# SIM3U164_B register map
File version: 1
CPU: 
Registers are 32-bit, read-write, reset 0x0 unless marked. A register's access mark holds for its fields unless they carry their own. Offsets are from the block's base; [hi:lo] are bit positions.

## PMU_0
Base 0x40048000
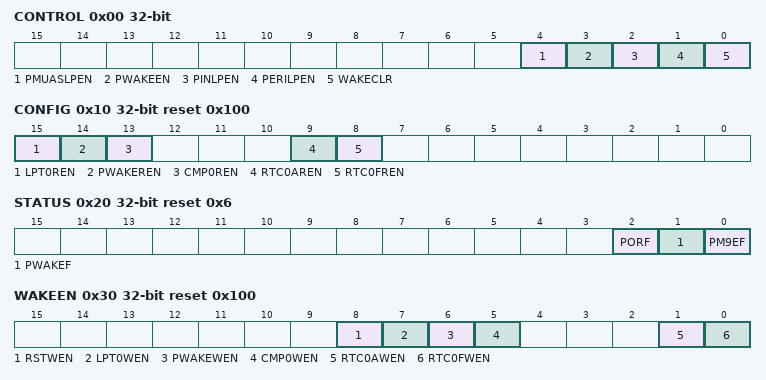
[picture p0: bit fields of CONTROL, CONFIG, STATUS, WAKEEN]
0x00 CONTROL — Module Control
  [4] PMUASLPEN — PMU Asleep Pin Enable.
    0=DISABLED (Disable the PMU Asleep pin.); 1=ENABLED (Enable the PMU Asleep pin.)
  [3] PWAKEEN — Pin Wake Match Enable.
    0=DISABLED (Disable Pin Wake.); 1=ENABLED (Enable Pin Wake.)
  [2] PINLPEN — Pin Low Power Enable.
    0=DISABLED (Disable the pin low power state.); 1=ENABLED (Enable the pin low power state. The pins will not be accessible in this state.)
  [1] PERILPEN — Peripheral Low Power Enable.
    0=DISABLED (Disable the peripheral low power state.); 1=ENABLED (Enable the peripheral low power state. The peripherals will not be accessible in this state.)
  [0] WAKECLR wo — Wakeup Source Clear.
    0=CLEAR (Clear all wakeup sources.)
0x10 CONFIG reset 0x100 — Module Configuration
  [15] LPT0REN — Low Power Timer RTC0/LPTIMER0 Reset Enable.
    0=DISABLED (An LPTIMER0 event does not cause the RTC0 and LPTIMER0 modules to reset.); 1=ENABLED (An LPTIMER0 event causes the RTC0 and LPTIMER0 modules to reset.)
  [14] PWAKEREN — Pin Wake RTC0/LPTIMER0 Reset Enable.
    0=DISABLED (A Pin Wake event does not cause the RTC0 and LPTIMER0 modules to reset.); 1=ENABLED (A Pin Wake event causes the RTC0 and LPTIMER0 modules to reset.)
  [13] CMP0REN — Comparator 0 RTC0/LPTIMER0 Reset Enable.
    0=DISABLED (A Comparator 0 event does not cause the RTC0 and LPTIMER0 modules to reset.); 1=ENABLED (A Comparator 0 event causes the RTC0 and LPTIMER0 modules to reset.)
  [9] RTC0AREN — RTC0 Alarm RTC0/LPTIMER0 Reset Enable.
    0=DISABLED (An RTC0 alarm event does not cause the RTC0 and LPTIMER0 modules to reset.); 1=ENABLED (An RTC0 alarm event causes the RTC0 and LPTIMER0 modules to reset.)
  [8] RTC0FREN — RTC0 Fail RTC0/LPTIMER0 Reset Enable.
    0=DISABLED (An RTC0 fail event does not cause the RTC0 and LPTIMER0 modules to reset.); 1=ENABLED (An RTC0 fail event causes the RTC0 and LPTIMER0 modules to reset.)
0x20 STATUS reset 0x6 — Module Status
  [2] PORF — Power-On Reset Flag.
    0=NOT_SET (A power-on reset did not occur since the last time PORF was cleared.); 1=SET (A power-on reset occurred.)
  [1] PWAKEF ro — Pin Wake Status Flag.
    0=SET (A Pin Wake event has occurred.); 1=NOT_SET (A Pin Wake event has not occurred.)
  [0] PM9EF — Power Mode 9 Exited Flag.
    0=NOT_SET (The device has not exited Power Mode 9.); 1=SET (The device has exited Power Mode 9. This bit must be cleared by firmware.)
0x30 WAKEEN reset 0x100 — Wake Source Enable
  [8] RSTWEN — Reset Pin Wake Enable.
    0=DISABLED (A /RESET Pin event does not wake the device.); 1=ENABLED (A /RESET Pin event awakens the device.)
  [7] LPT0WEN — Low Power Timer Wake Enable.
    0=DISABLED (An LPTIMER0 event does not wake the device.); 1=ENABLED (An LPTIMER0 event awakens the device.)
  [6] PWAKEWEN — Pin Wake Wake Enable.
    0=DISABLED (A Pin Wake event does not wake the device.); 1=ENABLED (A Pin Wake event awakens the device.)
  [5] CMP0WEN — Comparator 0 Wake Enable.
    0=DISABLED (A Comparator 0 event does not wake the device.); 1=ENABLED (A Comparator 0 event awakens the device.)
  [1] RTC0AWEN — RTC0 Alarm Wake Enable.
    0=DISABLED (An RTC0 alarm event does not wake the device.); 1=ENABLED (An RTC0 alarm event awakens the device.)
  [0] RTC0FWEN — RTC0 Fail Wake Enable.
    0=DISABLED (An RTC0 fail event does not wake the device.); 1=ENABLED (An RTC0 fail event awakens the device.)
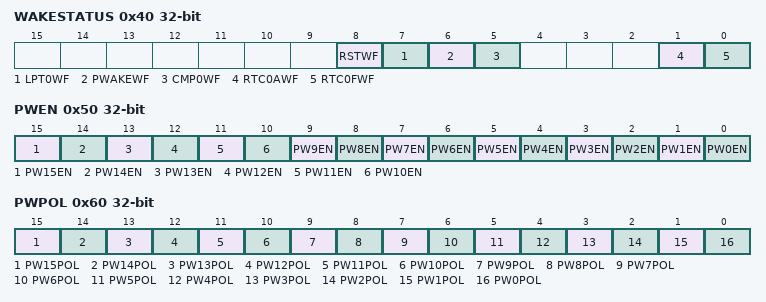
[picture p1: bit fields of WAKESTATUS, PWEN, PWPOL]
0x40 WAKESTATUS — Wake Source Status
  [8] RSTWF ro — Reset Pin Wake Flag.
    0=NOT_SET (A /RESET Pin event did not wake the device.); 1=SET (A /RESET Pin event woke the device.)
  [7] LPT0WF ro — Low Power Timer Wake Flag.
    0=NOT_SET (An LPTIMER0 event did not wake the device.); 1=SET (An LPTIMER0 event woke the device.)
  [6] PWAKEWF ro — Pin Wake Wake Flag.
    0=NOT_SET (A Pin Wake event did not wake the device.); 1=SET (A Pin Wake event woke the device.)
  [5] CMP0WF ro — Comparator 0 Wake Flag.
    0=NOT_SET (A Comparator 0 event did not wake the device.); 1=SET (A Comparator 0 event woke the device.)
  [1] RTC0AWF ro — RTC0 Alarm Wake Flag.
    0=NOT_SET (An RTC0 alarm event did not wake the device.); 1=SET (An RTC0 alarm event woke the device.)
  [0] RTC0FWF ro — RTC0 Fail Wake Flag.
    0=NOT_SET (An RTC0 fail event did not wake the device.); 1=SET (An RTC0 fail event woke the device.)
0x50 PWEN — Pin Wake Pin Enable
  [15] PW15EN — WAKE.15 Enable.
    0=DISABLED (WAKE.15 (PB3.3) is not used in the Pin Wake comparison.); 1=ENABLED (WAKE.15 (PB3.3) is used in the Pin Wake comparison.)
  [14] PW14EN — WAKE.14 Enable.
    0=DISABLED (WAKE.14 (PB3.2) is not used in the Pin Wake comparison.); 1=ENABLED (WAKE.14 (PB3.2) is used in the Pin Wake comparison.)
  [13] PW13EN — WAKE.13 Enable.
    0=DISABLED (WAKE.13 (PB3.1) is not used in the Pin Wake comparison.); 1=ENABLED (WAKE.13 (PB3.1) is used in the Pin Wake comparison.)
  [12] PW12EN — WAKE.12 Enable.
    0=DISABLED (WAKE.12 (PB3.0) is not used in the Pin Wake comparison.); 1=ENABLED (WAKE.12 (PB3.0) is used in the Pin Wake comparison.)
  [11] PW11EN — WAKE.11 Enable.
    0=DISABLED (WAKE.11 (RESERVED) is not used in the Pin Wake comparison.); 1=ENABLED (WAKE.11 (RESERVED) is used in the Pin Wake comparison.)
  [10] PW10EN — WAKE.10 Enable.
    0=DISABLED (WAKE.10 (RESERVED) is not used in the Pin Wake comparison.); 1=ENABLED (WAKE.10 (RESERVED) is used in the Pin Wake comparison.)
  [9] PW9EN — WAKE.9 Enable.
    0=DISABLED (WAKE.9 (RESERVED) is not used in the Pin Wake comparison.); 1=ENABLED (WAKE.9 (RESERVED) is used in the Pin Wake comparison.)
  [8] PW8EN — WAKE.8 Enable.
    0=DISABLED (WAKE.8 (RESERVED) is not used in the Pin Wake comparison.); 1=ENABLED (WAKE.8 (RESERVED) is used in the Pin Wake comparison.)
  [7] PW7EN — WAKE.7 Enable.
    0=DISABLED (WAKE.7 (RESERVED) is not used in the Pin Wake comparison.); 1=ENABLED (WAKE.7 (RESERVED) is used in the Pin Wake comparison.)
  [6] PW6EN — WAKE.6 Enable.
    0=DISABLED (WAKE.6 (RESERVED) is not used in the Pin Wake comparison.); 1=ENABLED (WAKE.6 (RESERVED) is used in the Pin Wake comparison.)
  [5] PW5EN — WAKE.5 Enable.
    0=DISABLED (WAKE.5 (PB1.1) is not used in the Pin Wake comparison.); 1=ENABLED (WAKE.5 (PB1.1) is used in the Pin Wake comparison.)
  [4] PW4EN — WAKE.4 Enable.
    0=DISABLED (WAKE.4 (PB1.0) is not used in the Pin Wake comparison.); 1=ENABLED (WAKE.4 (PB1.0) is used in the Pin Wake comparison.)
  [3] PW3EN — WAKE.3 Enable.
    0=DISABLED (WAKE.3 (PB0.15) is not used in the Pin Wake comparison.); 1=ENABLED (WAKE.3 (PB0.15) is used in the Pin Wake comparison.)
  [2] PW2EN — WAKE.2 Enable.
    0=DISABLED (WAKE.2 (PB0.14) is not used in the Pin Wake comparison.); 1=ENABLED (WAKE.2 (PB0.14) is used in the Pin Wake comparison.)
  [1] PW1EN — WAKE.1 Enable.
    0=DISABLED (WAKE.1 (PB0.13) is not used in the Pin Wake comparison.); 1=ENABLED (WAKE.1 (PB0.13) is used in the Pin Wake comparison.)
  [0] PW0EN — WAKE.0 Enable.
    0=DISABLED (WAKE.0 (PB0.12) is not used in the Pin Wake comparison.); 1=ENABLED (WAKE.0 (PB0.12) is used in the Pin Wake comparison.)
0x60 PWPOL — Pin Wake Pin Polarity Select
  [15] PW15POL — WAKE.15 Polarity Select.
    0=LOW (The WAKE.15 (PB3.3) comparison value is logic low.); 1=HIGH (The WAKE.15 (PB3.3) comparison value is logic high.)
  [14] PW14POL — WAKE.14 Polarity Select.
    0=LOW (The WAKE.14 (PB3.2) comparison value is logic low.); 1=HIGH (The WAKE.14 (PB3.2) comparison value is logic high.)
  [13] PW13POL — WAKE.13 Polarity Select.
    0=LOW (The WAKE.13 (PB3.1) comparison value is logic low.); 1=HIGH (The WAKE.13 (PB3.1) comparison value is logic high.)
  [12] PW12POL — WAKE.12 Polarity Select.
    0=LOW (The WAKE.12 (PB3.0) comparison value is logic low.); 1=HIGH (The WAKE.12 (PB3.0) comparison value is logic high.)
  [11] PW11POL — WAKE.11 Polarity Select.
    0=LOW (The WAKE.11 (RESERVED) comparison value is logic low.); 1=HIGH (The WAKE.11 (RESERVED) comparison value is logic high.)
  [10] PW10POL — WAKE.10 Polarity Select.
    0=LOW (The WAKE.10 (RESERVED) comparison value is logic low.); 1=HIGH (The WAKE.10 (RESERVED) comparison value is logic high.)
  [9] PW9POL — WAKE.9 Polarity Select.
    0=LOW (The WAKE.9 (RESERVED) comparison value is logic low.); 1=HIGH (The WAKE.9 (RESERVED) comparison value is logic high.)
  [8] PW8POL — WAKE.8 Polarity Select.
    0=LOW (The WAKE.8 (RESERVED) comparison value is logic low.); 1=HIGH (The WAKE.8 (RESERVED) comparison value is logic high.)
  [7] PW7POL — WAKE.7 Polarity Select.
    0=LOW (The WAKE.7 (RESERVED) comparison value is logic low.); 1=HIGH (The WAKE.7 (RESERVED) comparison value is logic high.)
  [6] PW6POL — WAKE.6 Polarity Select.
    0=LOW (The WAKE.6 (RESERVED) comparison value is logic low.); 1=HIGH (The WAKE.6 (RESERVED) comparison value is logic high.)
  [5] PW5POL — WAKE.5 Polarity Select.
    0=LOW (The WAKE.5 (PB1.1) comparison value is logic low.); 1=HIGH (The WAKE.5 (PB1.1) comparison value is logic high.)
  [4] PW4POL — WAKE.4 Polarity Select.
    0=LOW (The WAKE.4 (PB1.0) comparison value is logic low.); 1=HIGH (The WAKE.4 (PB1.0) comparison value is logic high.)
  [3] PW3POL — WAKE.3 Polarity Select.
    0=LOW (The WAKE.3 (PB0.15) comparison value is logic low.); 1=HIGH (The WAKE.3 (PB0.15) comparison value is logic high.)
  [2] PW2POL — WAKE.2 Polarity Select.
    0=LOW (The WAKE.2 (PB0.14) comparison value is logic low.); 1=HIGH (The WAKE.2 (PB0.14) comparison value is logic high.)
  [1] PW1POL — WAKE.1 Polarity Select.
    0=LOW (The WAKE.1 (PB0.13) comparison value is logic low.); 1=HIGH (The WAKE.1 (PB0.13) comparison value is logic high.)
  [0] PW0POL — WAKE.0 Polarity Select.
    0=LOW (The WAKE.0 (PB0.12) comparison value is logic low.); 1=HIGH (The WAKE.0 (PB0.12) comparison value is logic high.)
